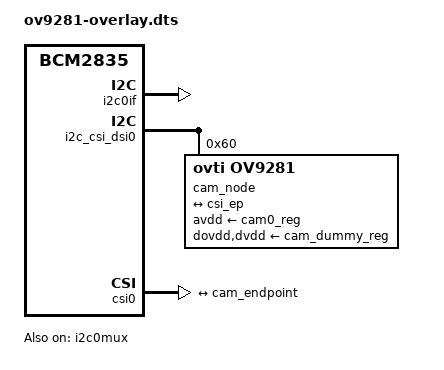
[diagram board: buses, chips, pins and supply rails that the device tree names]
/dts-v1/;
/plugin/;

/*
 * OV9281 on Raspberry Pi 5 CAM/DISP 0.
 * 1280x800 mono RAW10, 2 lanes. The register list is the 24 MHz /
 * 800 Mbps-per-lane table, so its link frequency is 400 MHz. This
 * module's crystal is 27 MHz, which scales that link to 450 MHz.
 * The Pi's own ov9282 driver rejects any clock other than 24 MHz.
 */

/ {
	compatible = "brcm,bcm2835";

	fragment@0 {
		target = <&i2c0if>;
		__overlay__ {
			status = "okay";
		};
	};

	fragment@1 {
		target = <&i2c0mux>;
		__overlay__ {
			status = "okay";
		};
	};

	fragment@2 {
		target = <&cam0_clk>;
		__overlay__ {
			status = "okay";
			clock-frequency = <27000000>;
		};
	};

	fragment@3 {
		target = <&i2c_csi_dsi0>;
		__overlay__ {
			#address-cells = <1>;
			#size-cells = <0>;
			status = "okay";

			cam_node: ov9281@60 {
				compatible = "ovti,ov9281";
				reg = <0x60>;
				status = "okay";

				clocks = <&cam0_clk>;
				clock-names = "xclk";

				avdd-supply = <&cam0_reg>;
				dovdd-supply = <&cam_dummy_reg>;
				dvdd-supply = <&cam_dummy_reg>;

				rotation = <0>;
				orientation = <2>;

				port {
					cam_endpoint: endpoint {
						clock-lanes = <0>;
						data-lanes = <1 2>;
						link-frequencies =
							/bits/ 64 <450000000>;
						remote-endpoint = <&csi_ep>;
					};
				};
			};
		};
	};

	fragment@4 {
		target = <&csi0>;
		__overlay__ {
			status = "okay";

			port {
				csi_ep: endpoint {
					remote-endpoint = <&cam_endpoint>;
					clock-lanes = <0>;
					data-lanes = <1 2>;
				};
			};
		};
	};
};
